AUTOSAR XML (schema 00046)
package /Cluster
  flexray cluster Chassis
    flexray physical channel ChassisA: channel-name=CHANNEL-A
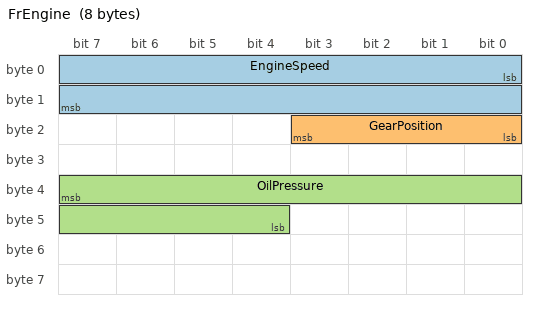
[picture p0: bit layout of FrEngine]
      frame FrEngine: frame-length=8, flexray-absolutely-scheduled-timing{communication-cycle=cycle-repetition={base-cycle=0, cycle-repetition=CYCLE-REPETITION-1}, slot-id=12}
        pdu EnginePdu: length=8, contained-i-pdu-props=header-id-short-header=0x010203
          signal EngineSpeed: start 0, 16 bit, little-endian, base-type=U16, compu {phys=raw*0.25 for raw 0..65535}, unit=rpm
          signal GearPosition: start 16, 4 bit, little-endian, base-type=U8, compu {0=Neutral, 1=First, 2=Second}
          signal OilPressure: start 39, 12 bit, big-endian, base-type=U16, compu {phys=raw*0.5-100 for raw 0..4095}, unit=kPa
      frame FrWheels: frame-length=8, flexray-absolutely-scheduled-timing{communication-cycle=cycle-repetition={base-cycle=1, cycle-repetition=CYCLE-REPETITION-4}, slot-id=40}
        pdu WheelPdu: length=8
          signal WheelSpeedFrontLeft: start 0, 16 bit, little-endian, base-type=U16, compu {phys=raw*0.01 for raw 0..65535}, unit=km/h
      frame FrStatus: frame-length=8, flexray-absolutely-scheduled-timing{communication-cycle=cycle-counter=3, slot-id=50}
        pdu StatusPdu: length=2, contained-i-pdu-props=header-id-short-header=0x0A0B0C
          signal AliveCounter: start 0, 8 bit, little-endian, base-type=U8, compu {identical}
    flexray physical channel ChassisB: channel-name=CHANNEL-B
      frame FrEngine: frame-length=8, flexray-absolutely-scheduled-timing{communication-cycle=cycle-repetition={base-cycle=0, cycle-repetition=CYCLE-REPETITION-1}, slot-id=12}
        carries pdu EnginePdu: start-position=0
package /ContainerIPdu
  container i pdu Bundle: length=64, contained-pdu-triggering=[EnginePdu_triggering, StatusPdu_triggering], header-type=SHORT-HEADER
package /Unit
  unit rpm: display-name=rpm
  unit kPa: display-name=kPa
  unit kmh: display-name=km/h
package /SwBaseType
  base type U8: category=FIXED_LENGTH, base-type-size=8, base-type-encoding=NONE
  base type U16: category=FIXED_LENGTH, base-type-size=16, base-type-encoding=NONE
package /System
  system TestSystem: category=SYSTEM_EXTRACT, container-i-pdu-header-byte-order=big-endian
